VERSION ""

NS_ :

BS_:

BU_: MSY_ECU Control
VAL_TABLE_ SNA_uint12 4095 "SNA" ;
VAL_TABLE_ SNA_uint8 255 "SNA" ;
VAL_TABLE_ SNA_uint16 65535 "SNA" ;

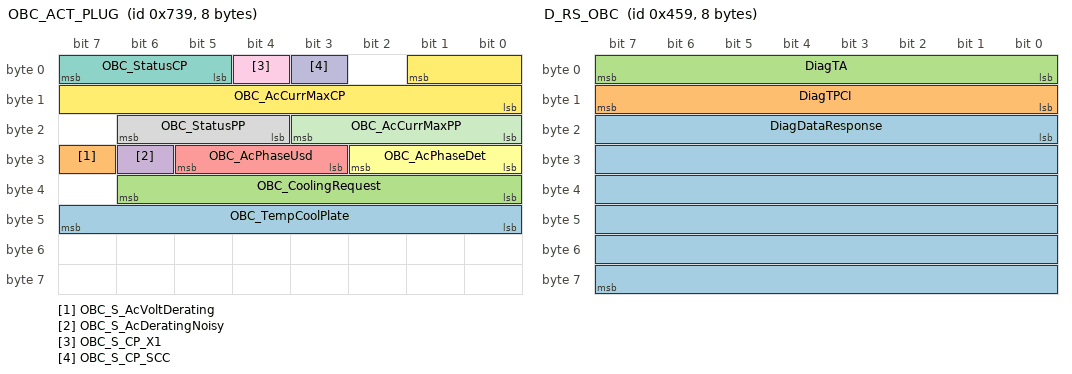
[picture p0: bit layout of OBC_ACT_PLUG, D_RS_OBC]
BO_ 1849 OBC_ACT_PLUG: 8 MSY_ECU
 SG_ OBC_TempCoolPlate : 47|8@0+ (1,-50) [-50|204] "GradC"  Control
 SG_ OBC_S_AcVoltDerating : 31|1@0+ (1,0) [0|1] ""  Control
 SG_ OBC_CoolingRequest : 38|7@0+ (1,0) [0|100] "%"  Control
 SG_ OBC_S_AcDeratingNoisy : 30|1@0+ (1,0) [0|1] ""  Control
 SG_ OBC_AcPhaseUsd : 29|3@0+ (1,0) [0|7] ""  Control
 SG_ OBC_AcPhaseDet : 26|3@0+ (1,0) [0|7] ""  Control
 SG_ OBC_StatusCP : 7|3@0+ (1,0) [0|7] ""  Control
 SG_ OBC_StatusPP : 22|3@0+ (1,0) [0|7] ""  Control
 SG_ OBC_S_CP_X1 : 4|1@0+ (1,0) [0|1] ""  Control
 SG_ OBC_S_CP_SCC : 3|1@0+ (1,0) [0|1] ""  Control
 SG_ OBC_AcCurrMaxPP : 19|4@0+ (1,0) [0|15] ""  Control
 SG_ OBC_AcCurrMaxCP : 1|10@0+ (0.1,0) [0|80] "A"  Control

BO_ 1113 D_RS_OBC: 8 MSY_ECU
 SG_ DiagDataResponse : 16|48@1+ (1,0) [0|0] ""  Control
 SG_ DiagTPCI : 8|8@1+ (1,0) [0|0] ""  Control
 SG_ DiagTA : 0|8@1+ (1,0) [0|0] ""  Control

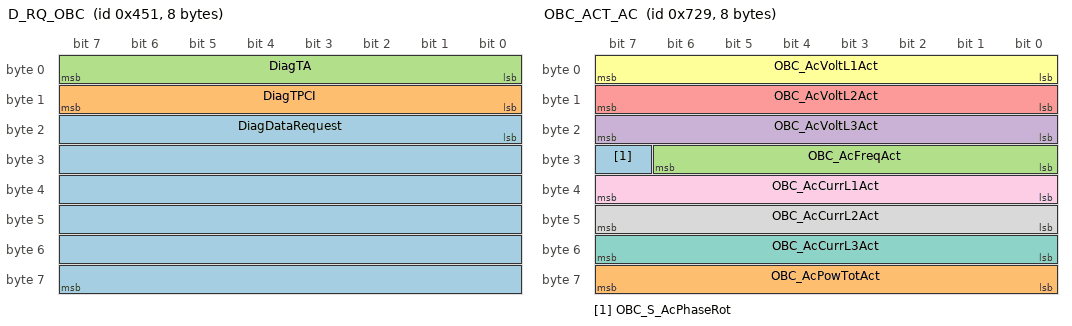
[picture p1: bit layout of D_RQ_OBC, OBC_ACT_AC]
BO_ 1105 D_RQ_OBC: 8 Control
 SG_ DiagDataRequest : 16|48@1+ (1,0) [0|0] ""  MSY_ECU
 SG_ DiagTPCI : 8|8@1+ (1,0) [0|0] ""  MSY_ECU
 SG_ DiagTA : 0|8@1+ (1,0) [0|0] ""  MSY_ECU

BO_ 1089 D_RQ_UDS: 8 Control
 SG_ FunctionalData : 0|64@1- (1,0) [0|0] ""  MSY_ECU

BO_ 2600147972 XCP_DTO_OBC: 8 MSY_ECU
 SG_ XCP_DTO_OBC : 7|64@0+ (1,0) [0|0] ""  Control

BO_ 2600147968 XCP_CRO_OBC: 8 Control
 SG_ XCP_CRO_OBC : 7|64@0+ (1,0) [0|0] ""  MSY_ECU

BO_ 1049 OBC_PARAM_TX: 8 MSY_ECU
 SG_ OBC_PARAM_RP : 7|64@0+ (1,0) [0|1.844674407371E+019] ""  Control

BO_ 1041 OBC_PARAM_RX: 8 Control
 SG_ OBC_PARAM_RQ : 7|64@0+ (1,0) [0|1.844674407371E+019] ""  MSY_ECU

BO_ 1833 OBC_ACT_AC: 8 MSY_ECU
 SG_ OBC_S_AcPhaseRot : 31|1@0+ (1,0) [0|1] ""  Control
 SG_ OBC_AcPowTotAct : 63|8@0+ (100,0) [0|25500] "W"  Control
 SG_ OBC_AcFreqAct : 30|7@0+ (1,0) [0|127] "Hz"  Control
 SG_ OBC_AcVoltL3Act : 23|8@0+ (2,0) [0|510] "V"  Control
 SG_ OBC_AcVoltL2Act : 15|8@0+ (2,0) [0|510] "V"  Control
 SG_ OBC_AcVoltL1Act : 7|8@0+ (2,0) [0|510] "V"  Control
 SG_ OBC_AcCurrL3Act : 55|8@0+ (1,-127) [-127|128] "A"  Control
 SG_ OBC_AcCurrL2Act : 47|8@0+ (1,-127) [-127|128] "A"  Control
 SG_ OBC_AcCurrL1Act : 39|8@0+ (1,-127) [-127|128] "A"  Control

BO_ 1832 OBC_ACT_LIM: 8 MSY_ECU
 SG_ OBC_AcCurrHwAvl : 55|8@0+ (0.5,0) [0|100] "A"  Control
 SG_ OBC_S_HwEnable : 58|1@0+ (1,0) [0|1] ""  Control
 SG_ OBC_S_AcDet : 60|1@0+ (1,0) [0|1] ""  Control
 SG_ OBC_S_ConLocked : 61|1@0+ (1,0) [0|1] ""  Control
 SG_ OBC_S_CtrlPilotDet : 62|1@0+ (1,0) [0|1] ""  Control
 SG_ OBC_S_ProximityDet : 63|1@0+ (1,0) [0|1] ""  Control
 SG_ OBC_S_HwWakeup : 59|1@0+ (1,0) [0|1] ""  Control
 SG_ OBC_StateAct : 23|3@0+ (1,0) [0|7] ""  Control
 SG_ OBC_StateCtrlPilot : 7|3@0+ (1,0) [0|7] ""  Control
 SG_ OBC_S_ProximityLim : 39|1@0+ (1,0) [0|1] ""  Control
 SG_ OBC_S_IntTempLim : 36|1@0+ (1,0) [0|1] ""  Control
 SG_ OBC_S_CtrlPilotLim : 38|1@0+ (1,0) [0|1] ""  Control
 SG_ OBC_S_ConTempLim : 37|1@0+ (1,0) [0|1] ""  Control
 SG_ OBC_S_AcCurrLim : 35|1@0+ (1,0) [0|1] ""  Control
 SG_ OBC_S_War : 56|1@0+ (1,0) [0|1] ""  Control
 SG_ OBC_S_Err : 57|1@0+ (1,0) [0|1] ""  Control
 SG_ OBC_S_DcHvVoltLim : 19|1@0+ (1,0) [0|1] ""  Control
 SG_ OBC_S_DcHvCurrLim : 20|1@0+ (1,0) [0|1] ""  Control
 SG_ OBC_AcCurrMaxAct : 34|11@0+ (0.1,-102.4) [-102.4|102.3] "A"  Control
 SG_ OBC_DcHvVoltAct : 4|13@0+ (0.1,0) [0|800] "V"  Control
 SG_ OBC_DcHvCurrAct : 18|11@0+ (0.1,-102.4) [-102.4|102.3] "A"  Control

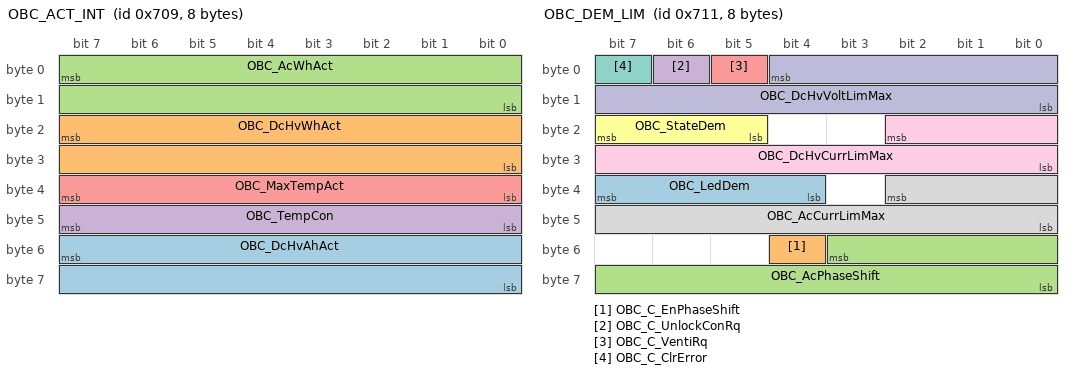
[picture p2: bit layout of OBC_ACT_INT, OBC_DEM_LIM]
BO_ 1801 OBC_ACT_INT: 8 MSY_ECU
 SG_ OBC_DcHvAhAct : 55|16@0+ (0.01,0) [0|655.35] "Ah"  Control
 SG_ OBC_DcHvWhAct : 23|16@0+ (1,0) [0|65535] "Wh"  Control
 SG_ OBC_AcWhAct : 7|16@0+ (1,0) [0|65535] "Wh"  Control
 SG_ OBC_TempCon : 47|8@0+ (1,-50) [-50|204] "GradC"  Control
 SG_ OBC_MaxTempAct : 39|8@0+ (1,0) [0|254] "GradC"  Control

BO_ 1945 OBC_ACT_ERR: 8 MSY_ECU
 SG_ OBC_E_LatchFPGA : 29|1@0+ (1,0) [0|1] ""  Control
 SG_ OBC_E_Inernal : 12|1@0+ (1,0) [0|1] ""  Control
 SG_ OBC_E_AcInterruption : 18|1@0+ (1,0) [0|1] ""  Control
 SG_ OBC_W_PRELOAD : 59|1@0+ (1,0) [0|1] ""  Control
 SG_ OBC_W_TempInt : 41|1@0+ (1,0) [0|1] ""  Control
 SG_ OBC_E_TempCon : 20|1@0+ (1,0) [0|1] ""  Control
 SG_ OBC_E_DcHvVoltRange : 19|1@0+ (1,0) [0|1] ""  Control
 SG_ OBC_E_UZK : 28|1@0+ (1,0) [0|1] ""  Control
 SG_ OBC_E_TPON : 27|1@0+ (1,0) [0|1] ""  Control
 SG_ OBC_E_BURST : 26|1@0+ (1,0) [0|1] ""  Control
 SG_ OBC_E_PRELOAD : 25|1@0+ (1,0) [0|1] ""  Control
 SG_ OBC_E_TempInt : 13|1@0+ (1,0) [0|1] ""  Control
 SG_ OBC_W_FPGA : 56|1@0+ (1,0) [0|1] ""  Control
 SG_ OBC_W_CanTimeout : 48|1@0+ (1,0) [0|1] ""  Control
 SG_ OBC_E_WrongFPGA : 1|1@0+ (1,0) [0|1] ""  Control
 SG_ OBC_W_AcVoltage : 57|1@0+ (1,0) [0|1] ""  Control
 SG_ OBC_W_AcFrequency : 58|1@0+ (1,0) [0|1] ""  Control
 SG_ OBC_W_ConLocked : 55|1@0+ (1,0) [0|1] ""  Control
 SG_ OBC_E_OverTemp : 31|1@0+ (1,0) [0|1] ""  Control
 SG_ OBC_W_PowRed : 40|1@0+ (1,0) [0|1] ""  Control
 SG_ OBC_E_WrongHW : 0|1@0+ (1,0) [0|1] ""  Control
 SG_ OBC_E_ConLocked : 21|1@0+ (1,0) [0|1] ""  Control
 SG_ OBC_E_IntSupply : 15|1@0+ (1,0) [0|1] ""  Control
 SG_ OBC_E_DcHvVoltRed : 14|1@0+ (1,0) [0|1] ""  Control
 SG_ OBC_E_HvIsoPos : 9|1@0+ (1,0) [0|1] ""  Control
 SG_ OBC_E_HvIsoNeg : 10|1@0+ (1,0) [0|1] ""  Control
 SG_ OBC_E_NVSRam : 5|1@0+ (1,0) [0|1] ""  Control
 SG_ OBC_E_FpgaInit : 2|1@0+ (1,0) [0|1] ""  Control
 SG_ OBC_E_Flash : 6|1@0+ (1,0) [0|1] ""  Control
 SG_ OBC_E_Interlock : 22|1@0+ (1,0) [0|1] ""  Control
 SG_ OBC_E_Crash : 23|1@0+ (1,0) [0|1] ""  Control
 SG_ OBC_E_CanValue : 17|1@0+ (1,0) [0|1] ""  Control
 SG_ OBC_E_CanMsgLost : 16|1@0+ (1,0) [0|1] ""  Control
 SG_ OBC_W_Watchdog : 39|1@0+ (1,0) [0|1] ""  Control
 SG_ OBC_W_CanTx : 51|1@0+ (1,0) [0|1] ""  Control
 SG_ OBC_W_CanRx : 50|1@0+ (1,0) [0|1] ""  Control
 SG_ OBC_W_CanOff : 49|1@0+ (1,0) [0|1] ""  Control
 SG_ OBC_E_OsTrap : 7|1@0+ (1,0) [0|1] ""  Control

BO_ 1809 OBC_DEM_LIM: 8 Control
 SG_ OBC_LedDem : 39|4@0+ (1,0) [0|1] ""  MSY_ECU
 SG_ OBC_C_EnPhaseShift : 52|1@0+ (1,0) [0|1] ""  MSY_ECU
 SG_ OBC_AcPhaseShift : 51|12@0+ (0.1,0) [0|360] "°"  MSY_ECU
 SG_ OBC_C_UnlockConRq : 6|1@0+ (1,0) [0|1] ""  MSY_ECU
 SG_ OBC_C_VentiRq : 5|1@0+ (1,0) [0|1] ""  MSY_ECU
 SG_ OBC_StateDem : 23|3@0+ (1,0) [0|1] ""  MSY_ECU
 SG_ OBC_C_ClrError : 7|1@0+ (1,0) [0|1] ""  MSY_ECU
 SG_ OBC_AcCurrLimMax : 34|11@0+ (0.1,-102.4) [-102.4|102.3] "A"  MSY_ECU
 SG_ OBC_DcHvCurrLimMax : 18|11@0+ (0.1,-102.4) [-102.4|102.3] "A"  MSY_ECU
 SG_ OBC_DcHvVoltLimMax : 4|13@0+ (0.1,0) [0|819.1] "V"  MSY_ECU

CM_ BU_ MSY_ECU "on-board charger";
CM_ SG_ 1849 OBC_TempCoolPlate "Actual temperatur cool plate";
CM_ SG_ 1849 OBC_S_AcVoltDerating "OBC is derating  MAINS (AC Voltage)";
CM_ SG_ 1849 OBC_S_AcDeratingNoisy "OBC is derating due to very noisy MAINS (AC Voltage)";
CM_ SG_ 1849 OBC_AcPhaseUsd "AC input number of phases used";
CM_ SG_ 1849 OBC_AcPhaseDet "AC input number of phases detected";
CM_ SG_ 1849 OBC_StatusCP "Status Control pilot";
CM_ SG_ 1849 OBC_StatusPP "Status Proximity";
CM_ SG_ 1849 OBC_S_CP_X1 "Control pilot signal detected with 100%";
CM_ SG_ 1849 OBC_S_CP_SCC "Control pilot signal detected with 5%";
CM_ SG_ 1849 OBC_AcCurrMaxPP "Maximum AC current Proximity";
CM_ SG_ 1849 OBC_AcCurrMaxCP "Maximum AC current Control Pilot";
CM_ BO_ 1113 "Diagnose Response";
CM_ BO_ 1105 "Diagnose Physical Request";
CM_ BO_ 1089 "Diagnose Functional Request";
CM_ BO_ 2600147972 "XCP Slave: Data Transmission Object";
CM_ BO_ 2600147968 "XCP Master: Command Recieive Object";
CM_ BO_ 1049 "OBC internal parameter transmit";
CM_ SG_ 1049 OBC_PARAM_RP "OBC PARAM response";
CM_ BO_ 1041 "OBC internal parameter receive";
CM_ SG_ 1041 OBC_PARAM_RQ "OBC PARAM request";
CM_ BO_ 1833 "Actual AC value";
CM_ SG_ 1833 OBC_S_AcPhaseRot "AC phase rotation (CW / CCW)";
CM_ SG_ 1833 OBC_AcPowTotAct "Actual AC power total";
CM_ SG_ 1833 OBC_AcFreqAct "Actual AC frequency";
CM_ SG_ 1833 OBC_AcVoltL3Act "Actual AC voltage L3 (reads zero during 1-phase operation)";
CM_ SG_ 1833 OBC_AcVoltL2Act "Actual AC voltage L2 (reads zero during 1-phase operation)";
CM_ SG_ 1833 OBC_AcVoltL1Act "Actual AC voltage L1";
CM_ SG_ 1833 OBC_AcCurrL3Act "Actual AC current L3 (PRC value shown during 1-phase operation)";
CM_ SG_ 1833 OBC_AcCurrL2Act "Actual AC current L2 (PRC value shown during 1-phase operation)";
CM_ SG_ 1833 OBC_AcCurrL1Act "Actual AC current L1";
CM_ BO_ 1832 "Actual limiter by CAN";
CM_ SG_ 1832 OBC_AcCurrHwAvl "Available AC current";
CM_ SG_ 1832 OBC_S_HwEnable "Indicates if hardware enabled";
CM_ SG_ 1832 OBC_S_AcDet "AC input detected";
CM_ SG_ 1832 OBC_S_ConLocked "Connector locked";
CM_ SG_ 1832 OBC_S_CtrlPilotDet "Control pilot signal detected";
CM_ SG_ 1832 OBC_S_ProximityDet "Valid Proximity signal detected";
CM_ SG_ 1832 OBC_S_HwWakeup "Hardware wakup detected";
CM_ SG_ 1832 OBC_StateAct "State On-Board Charger (see state machine)";
CM_ SG_ 1832 OBC_StateCtrlPilot "State ControlPilot (see IEC 61851)";
CM_ SG_ 1832 OBC_S_ProximityLim "Output power limited by proximity resistor value";
CM_ SG_ 1832 OBC_S_IntTempLim "Output power limited by internal temperature";
CM_ SG_ 1832 OBC_S_CtrlPilotLim "Output power limited by control pilot signal";
CM_ SG_ 1832 OBC_S_ConTempLim "Output power limited by conenctor temperature";
CM_ SG_ 1832 OBC_S_AcCurrLim "Output power limited by AC current";
CM_ SG_ 1832 OBC_S_War "Warning condition on";
CM_ SG_ 1832 OBC_S_Err "An error has been detected";
CM_ SG_ 1832 OBC_S_DcHvVoltLim "Output power limited by output voltage";
CM_ SG_ 1832 OBC_S_DcHvCurrLim "Output power limited by output current";
CM_ SG_ 1832 OBC_AcCurrMaxAct "Maximum actual AC current (L1/L2/L3)";
CM_ SG_ 1832 OBC_DcHvVoltAct "Actual HV battery output voltage";
CM_ SG_ 1832 OBC_DcHvCurrAct "Actual HV battery output current";
CM_ BO_ 1801 "Actual intern value";
CM_ SG_ 1801 OBC_DcHvAhAct "Actual DC Ah";
CM_ SG_ 1801 OBC_DcHvWhAct "Actual DC kWh";
CM_ SG_ 1801 OBC_AcWhAct "Actual AC kWh";
CM_ SG_ 1801 OBC_TempCon "Actual temperatur connector";
CM_ SG_ 1801 OBC_MaxTempAct "Maximum actual internal temperature";
CM_ BO_ 1945 "Actual error and warning";
CM_ SG_ 1945 OBC_E_LatchFPGA "Error - Latch FPGA";
CM_ SG_ 1945 OBC_E_Inernal "Error-  internal error";
CM_ SG_ 1945 OBC_E_AcInterruption "Error-  AC Interruption";
CM_ SG_ 1945 OBC_W_PRELOAD "Warning - to many preloaded";
CM_ SG_ 1945 OBC_W_TempInt "Warning - power reduction due to internal temperature";
CM_ SG_ 1945 OBC_E_TempCon "Error - Connector temperature";
CM_ SG_ 1945 OBC_E_DcHvVoltRange "Error - HVDC voltage out of range";
CM_ SG_ 1945 OBC_E_UZK "Error - DC voltage to low";
CM_ SG_ 1945 OBC_E_TPON "Error - serial relay has not been switched";
CM_ SG_ 1945 OBC_E_BURST "Error - output voltage to low";
CM_ SG_ 1945 OBC_E_PRELOAD "Error - DC-Link (Mains!!) not preloaded";
CM_ SG_ 1945 OBC_E_TempInt "Error-  internal temperature wrong";
CM_ SG_ 1945 OBC_W_FPGA "Warning - FPGA shutdown";
CM_ SG_ 1945 OBC_W_CanTimeout "Warning - some CAN messages lost";
CM_ SG_ 1945 OBC_E_WrongFPGA "Error - wrong FPGA (doesn't match SW)";
CM_ SG_ 1945 OBC_W_AcVoltage "Warning - AC voltage out of specs";
CM_ SG_ 1945 OBC_W_AcFrequency "Warning - AC frequency out of specs";
CM_ SG_ 1945 OBC_W_ConLocked "Warning - Connector not locked";
CM_ SG_ 1945 OBC_E_OverTemp "Error - over temperature (charge coupler or internal)";
CM_ SG_ 1945 OBC_W_PowRed "Warning - power reduction due to internal conditions";
CM_ SG_ 1945 OBC_E_WrongHW "Error - wrong Hardware (doesn't match SW)";
CM_ SG_ 1945 OBC_E_ConLocked "reserved";
CM_ SG_ 1945 OBC_E_IntSupply "Error - intern supply fault";
CM_ SG_ 1945 OBC_E_DcHvVoltRed "Error - HV voltage redundant value different from main value";
CM_ SG_ 1945 OBC_E_HvIsoPos "reserved";
CM_ SG_ 1945 OBC_E_HvIsoNeg "reserved";
CM_ SG_ 1945 OBC_E_NVSRam "Error - NVSRAM check sum failure";
CM_ SG_ 1945 OBC_E_FpgaInit "Error - FPGA Initialization";
CM_ SG_ 1945 OBC_E_Flash "Error - Flash memory checksum failure";
CM_ SG_ 1945 OBC_E_Interlock "reserved";
CM_ SG_ 1945 OBC_E_Crash "Error - crash detected";
CM_ SG_ 1945 OBC_E_CanValue "Error - Commanded value is out of specified range";
CM_ SG_ 1945 OBC_E_CanMsgLost "Error - CAN timeout, no control message received";
CM_ SG_ 1945 OBC_W_Watchdog "Warning - Internal Watchdog Timeout";
CM_ SG_ 1945 OBC_W_CanTx "Warning - CAN transmit error counter > 127";
CM_ SG_ 1945 OBC_W_CanRx "Warning - CAN receive error counter > 127";
CM_ SG_ 1945 OBC_W_CanOff "Warning - CAN receive error counter > 127";
CM_ SG_ 1945 OBC_E_OsTrap "Error - OS trap encountered";
CM_ BO_ 1809 "Demand limiter by CAN";
CM_ SG_ 1809 OBC_LedDem "Charge LED demanded";
CM_ SG_ 1809 OBC_C_EnPhaseShift "AC power factor request";
CM_ SG_ 1809 OBC_AcPhaseShift "AC phase shift ( cos(phase shift) = power factor ) (not implemented)";
CM_ SG_ 1809 OBC_C_UnlockConRq "Unlock connector request";
CM_ SG_ 1809 OBC_C_VentiRq "Control pilot ventilation request";
CM_ SG_ 1809 OBC_StateDem "OBC state (see state machine)";
CM_ SG_ 1809 OBC_C_ClrError "Clear error latch";
CM_ SG_ 1809 OBC_AcCurrLimMax "Maximum AC current";
CM_ SG_ 1809 OBC_DcHvCurrLimMax "Maximum HV current";
CM_ SG_ 1809 OBC_DcHvVoltLimMax "Maximum HV voltage";
BA_DEF_ BO_  "DiagConnection" HEX 0 65535;
BA_DEF_ BO_  "DiagRequest" ENUM  "No","Yes";
BA_DEF_ BO_  "DiagResponse" ENUM  "No","Yes";
BA_DEF_  "BusSpeed" STRING ;
BA_DEF_ SG_  "GenSigSendType" ENUM  "Cyclic","OnWrite","OnWriteWithRepetition","OnChange","OnChangeWithRepetition","IfActive","IfActiveWithRepetition","NoSigSendType";
BA_DEF_ BO_  "GenMsgCycleTime" INT 0 0;
BA_DEF_ BO_  "GenMsgSendType" ENUM  "Cyclic","not_used","not_used","not_used","not_used","Cyclic","not_used","IfActive","NoMsgSendType";
BA_DEF_  "DBName" STRING ;
BA_DEF_  "BusType" STRING ;
BA_DEF_  "NmAsrTimeoutTime" INT 1 65535;
BA_DEF_  "NmAsrWaitBusSleepTime" INT 1 65535;
BA_DEF_  "NmAsrRepeatMessageTime" INT 1 65535;
BA_DEF_  "NmAsrMessageCount" INT 1 256;
BA_DEF_  "NmAsrBaseAddress" HEX 235487232 2147483647;
BA_DEF_  "NmAsrCanMsgCycleTime" INT 1 65535;
BA_DEF_DEF_  "DiagConnection" 0;
BA_DEF_DEF_  "DiagRequest" "No";
BA_DEF_DEF_  "DiagResponse" "No";
BA_DEF_DEF_  "BusSpeed" "500k";
BA_DEF_DEF_  "GenSigSendType" "Cyclic";
BA_DEF_DEF_  "GenMsgCycleTime" 0;
BA_DEF_DEF_  "GenMsgSendType" "NoMsgSendType";
BA_DEF_DEF_  "DBName" "";
BA_DEF_DEF_  "BusType" "CAN";
BA_DEF_DEF_  "NmAsrTimeoutTime" 1000;
BA_DEF_DEF_  "NmAsrWaitBusSleepTime" 750;
BA_DEF_DEF_  "NmAsrRepeatMessageTime" 800;
BA_DEF_DEF_  "NmAsrMessageCount" 256;
BA_DEF_DEF_  "NmAsrBaseAddress" 506724352;
BA_DEF_DEF_  "NmAsrCanMsgCycleTime" 200;
BA_ "DBName" "CCAN";
BA_ "GenMsgCycleTime" BO_ 1849 100;
BA_ "GenMsgSendType" BO_ 1849 0;
BA_ "DiagResponse" BO_ 1113 1;
BA_ "DiagConnection" BO_ 1113 1113;
BA_ "DiagRequest" BO_ 1105 1;
BA_ "DiagConnection" BO_ 1105 1113;
BA_ "DiagRequest" BO_ 1089 1;
BA_ "DiagConnection" BO_ 1089 1089;
BA_ "GenMsgSendType" BO_ 1049 7;
BA_ "GenMsgSendType" BO_ 1041 7;
BA_ "GenMsgSendType" BO_ 1833 0;
BA_ "GenMsgCycleTime" BO_ 1833 100;
BA_ "GenMsgSendType" BO_ 1832 0;
BA_ "GenMsgCycleTime" BO_ 1832 100;
BA_ "GenMsgSendType" BO_ 1801 0;
BA_ "GenMsgCycleTime" BO_ 1801 100;
BA_ "GenMsgSendType" BO_ 1945 0;
BA_ "GenMsgCycleTime" BO_ 1945 1000;
BA_ "GenMsgSendType" BO_ 1809 0;
BA_ "GenMsgCycleTime" BO_ 1809 100;
VAL_ 1849 OBC_CoolingRequest 127 "SNA" ;
VAL_ 1849 OBC_AcPhaseUsd 7 "SNAA" 3 "THREE_PHA" 2 "TWO_PHA" 1 "ONE_PHA" 0 "NO_PHA" ;
VAL_ 1849 OBC_AcPhaseDet 7 "NAA" 3 "THREE_PHAS" 2 "TWO_PHAS" 1 "ONE_PHAS" 0 "NO_PHAS" ;
VAL_ 1849 OBC_StatusCP 7 "NNA" 3 "CTRLPILOT_VALID" 2 "CTRLPILOT_INVALID" 1 "CTRLPILOT_FREQOUT" 0 "CTRLPILOT_OVERFLOW" ;
VAL_ 1849 OBC_StatusPP 7 "NNAA" 5 "PROXD_NOT_CONNECTED" 4 "PROXD_CIRCUIT_ERRATIC" 3 "PROXD_CIRCUIT_HIGH" 2 "PROXD_CIRCUIT_LOW" 1 "PROXD_CIRCUIT_RANGE" 0 "PROXD_DETECTED" ;
VAL_ 1849 OBC_AcCurrMaxPP 7 "PPNA" 4 "63 A" 3 "32 A" 2 "20 A" 1 "13 A" 0 "0 A" ;
VAL_ 1833 OBC_S_AcPhaseRot 1 "anticlockwise" 0 "clockwise" ;
VAL_ 1832 OBC_StateAct 5 "OBC_Shutdown" 4 "OBC_Charge" 3 "OBC_Ready2Charge" 2 "OBC_Standby" 1 "OBC_Wakeup" 0 "OBC_Sleep" ;
VAL_ 1832 OBC_StateCtrlPilot 7 "None" 5 "F" 4 "E" 3 "D" 2 "C" 1 "B" 0 "A" ;
VAL_ 1801 OBC_DcHvAhAct 255 "NA" ;
VAL_ 1801 OBC_DcHvWhAct 255 "NA" ;
VAL_ 1801 OBC_AcWhAct 255 "NA" ;
VAL_ 1809 OBC_StateDem 7 "NNNNA" 6 "OBC_StateDem_Sleep" 1 "OBC_StateDem_Charge" 0 "OBC_StateDem_Standby" ;
